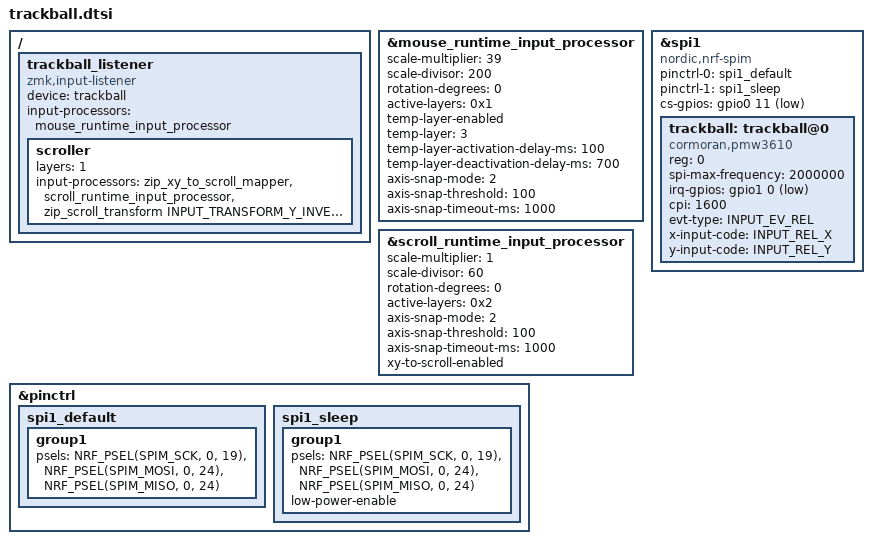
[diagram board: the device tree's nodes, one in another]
#include <zephyr/dt-bindings/input/input-event-codes.h>
#include <dt-bindings/zmk/input_transform.h>
#include <input/processors.dtsi>
#include <input/processors/runtime-input-processor.dtsi>

// Defaults captured from DYA Studio. Its rounded display shows 0.20x and 0.02x.
&mouse_runtime_input_processor {
    scale-multiplier = <39>;
    scale-divisor = <200>;
    rotation-degrees = <0>;
    active-layers = <0x1>; // BASE (layer 0) remains active beneath other layers.
    temp-layer-enabled;
    temp-layer = <3>; // MOUSE
    temp-layer-activation-delay-ms = <100>;
    temp-layer-deactivation-delay-ms = <700>;
    axis-snap-mode = <2>; // Y axis, matching the current Studio configuration.
    axis-snap-threshold = <100>;
    axis-snap-timeout-ms = <1000>;
};

&scroll_runtime_input_processor {
    scale-multiplier = <1>;
    scale-divisor = <60>;
    rotation-degrees = <0>;
    active-layers = <0x2>; // SYMBOL (layer 1)
    axis-snap-mode = <2>;
    axis-snap-threshold = <100>;
    axis-snap-timeout-ms = <1000>;
    xy-to-scroll-enabled;
    // Temporary layer, axis inversion, and XY swap remain disabled.
};

&pinctrl {
    spi1_default: spi1_default {
        group1 {
            psels = <NRF_PSEL(SPIM_SCK, 0, 19)>,
                <NRF_PSEL(SPIM_MOSI, 0, 24)>,
                <NRF_PSEL(SPIM_MISO, 0, 24)>;
        };
    };

    spi1_sleep: spi1_sleep {
        group1 {
            psels = <NRF_PSEL(SPIM_SCK, 0, 19)>,
                <NRF_PSEL(SPIM_MOSI, 0, 24)>,
                <NRF_PSEL(SPIM_MISO, 0, 24)>;
            low-power-enable;
        };
    };
};

&spi1 {
    status = "okay";
    compatible = "nordic,nrf-spim";
    pinctrl-0 = <&spi1_default>;
    pinctrl-1 = <&spi1_sleep>;
    pinctrl-names = "default", "sleep";
    cs-gpios = <&gpio0 11 GPIO_ACTIVE_LOW>;

    trackball: trackball@0 {
        status = "okay";
        compatible = "cormoran,pmw3610";
        reg = <0>;
        spi-max-frequency = <2000000>;
        irq-gpios = <&gpio1 0 (GPIO_ACTIVE_LOW | GPIO_PULL_UP)>;
        cpi = <1600>;
        evt-type = <INPUT_EV_REL>;
        x-input-code = <INPUT_REL_X>;
        y-input-code = <INPUT_REL_Y>;
    };
};

/ {
    trackball_listener {
        status = "okay";
        compatible = "zmk,input-listener";
        device = <&trackball>;
        input-processors = <&mouse_runtime_input_processor>;

        scroller {
            // Replace the mouse processor while SYMBOL is active, including
            // when the temporary MOUSE layer is still active. No process-next.
            layers = <1>; // SYMBOL
            input-processors =
                <&zip_xy_to_scroll_mapper &scroll_runtime_input_processor>,
                <&zip_scroll_transform INPUT_TRANSFORM_Y_INVERT>;
        };
    };
};
